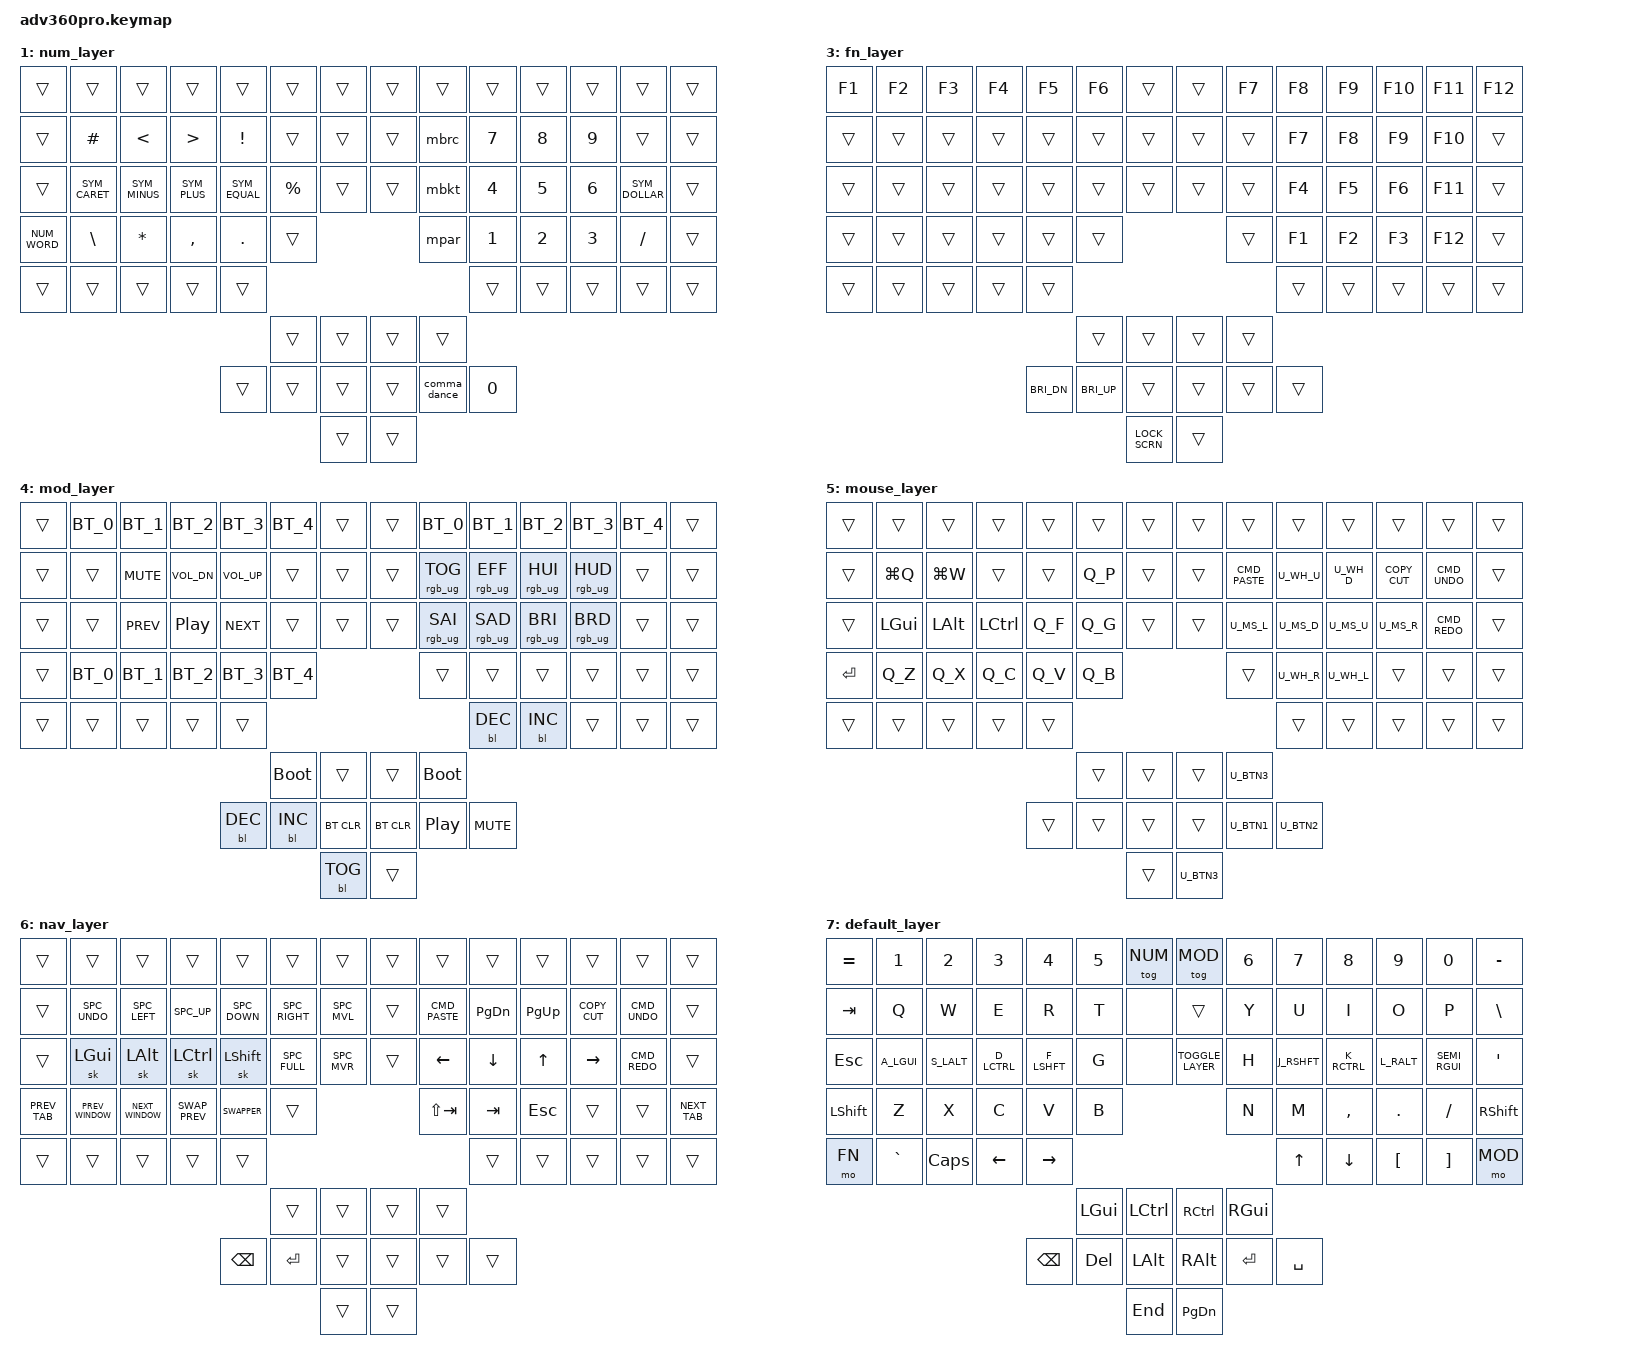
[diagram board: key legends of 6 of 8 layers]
#include <behaviors.dtsi>
#include <dt-bindings/zmk/keys.h>
#include <dt-bindings/zmk/bt.h>
#include <dt-bindings/zmk/outputs.h>
#include <dt-bindings/zmk/rgb.h>
#include <dt-bindings/zmk/backlight.h>

#include "adv360pro_keypos.h"
#include "zmk_helper.h"

/* definitions for mouse layer */
#include "mouse.h"

#define ___ &trans

/* Layer references  */
#define QWERTY 0
#define NUM 1
#define SYM 2
#define FN 3
#define MOD 4
#define MS 5
#define NAV 6
#define DEFAULT 7

/* Global settings */
#include "general.h"

/* Home row mods */
#include "homerow_mods.h"

/* Macros and shortcuts */
#include "custom_behaviors.h"

/ {
    /* use urobs matrix transform for correct key mapping */
    chosen {
        zmk,matrix_transform = &urobs_transform;
    };

    keymap {
        compatible = "zmk,keymap";

// QWERTY base
        base_layer {
            bindings = <
// ╭─────────────╮╭─────────────┬─────────────┬─────────────┬─────────────┬─────────────╮╭─────────────╮  ╭─────────────╮╭─────────────┬─────────────┬─────────────┬─────────────┬─────────────╮╭─────────────╮
     &kp EQUAL        &kp N1        &kp N2        &kp N3        &kp N4        &kp N5         &tog NUM         &mo MOD        &kp N6        &kp N7        &kp N8        &kp N9        &kp N0         LOCK_SCRN
// ╰─────────────╯╰─────────────┴─────────────┴─────────────┴─────────────┴─────────────╯╰─────────────╯  ╰─────────────╯╰─────────────┴─────────────┴─────────────┴─────────────┴─────────────╯╰─────────────╯
// ╭─────────────╮╭─────────────┬─────────────┬─────────────┬─────────────┬─────────────╮╭─────────────╮  ╭─────────────╮╭─────────────┬─────────────┬─────────────┬─────────────┬─────────────╮╭─────────────╮
     &kp TAB          &kp Q         &kp W         &kp E         &kp R         &kp T          SWAP_PREV        &tog MS        &kp Y         &kp U         &kp I         &kp O         &kp P          &kp BSLH
// ├─────────────┤├─────────────┼─────────────┼─────────────┼─────────────┼─────────────┤├─────────────┤  ├─────────────┤├─────────────┼─────────────┼─────────────┼─────────────┼─────────────┤├─────────────┤
     &kp ESC          A_LGUI        S_LALT        D_LCTRL       F_LSHFT       &kp G          SWAPPER          TOGGLE_LAYER   &kp H         J_RSHFT       K_RCTRL       L_RALT        SEMI_RGUI      &kp SQT
// ├─────────────┤├─────────────┼─────────────┼─────────────┼─────────────┼─────────────┤╰─────────────╯  ╰─────────────╯├─────────────┼─────────────┼─────────────┼─────────────┼─────────────┤├─────────────┤
     NUM_WORD         &kp Z         &kp X         &kp C         &kp V         &kp B                                          &kp N         &kp M         &kp COMMA     &kp DOT       &kp FSLH       &caps_dance
// ╰─────────────╯╰─────────────┴─────────────┴─────────────┴─────────────┴─────────────╯                                ╰─────────────┴─────────────┴─────────────┴─────────────┴─────────────╯╰─────────────╯
// ╭─────────────╮╭─────────────┬─────────────┬─────────────┬─────────────╮                                                            ╭─────────────┬─────────────┬─────────────┬─────────────╮╭─────────────╮
     &mo FN           NUM_WORD      &sk LHYP      &kp LEFT      &kp RIGHT                                                                  &kp UP        &kp DOWN      &sk RHYP      &caps_dance    &mo MOD
// ╰─────────────╯╰─────────────┴─────────────┴─────────────┴─────────────╯╭─────────────┬─────────────╮  ╭─────────────┬─────────────╮╰─────────────┴─────────────┴─────────────┴─────────────╯╰─────────────╯
                                                                             &mo NAV       &caps_dance      NUM_WORD      &mo MS
//                                                           ╭─────────────┼─────────────┼─────────────┤  ├─────────────┼─────────────┼─────────────╮
                                                               BSPC_SYM      SHFT_NUM      &lt MS HOME      &kp END       SPC_NAV       RET_HYP
//                                                           │             │             ├─────────────┤  ├─────────────┤             │             │
                                                                                           &lt MS TAB       &lt FN ESC
//                                                           ╰─────────────┴─────────────┴─────────────╯  ╰─────────────┴─────────────┴─────────────╯
            >;
        };


        num_layer {
            bindings = <
// ╭─────────────╮╭─────────────┬─────────────┬─────────────┬─────────────┬─────────────╮╭─────────────╮  ╭─────────────╮╭─────────────┬─────────────┬─────────────┬─────────────┬─────────────╮╭─────────────╮
     ___              ___           ___           ___           ___           ___             ___              ___            ___           ___           ___           ___           ___            ___
// ╰─────────────╯╰─────────────┴─────────────┴─────────────┴─────────────┴─────────────╯╰─────────────╯  ╰─────────────╯╰─────────────┴─────────────┴─────────────┴─────────────┴─────────────╯╰─────────────╯
// ╭─────────────╮╭─────────────┬─────────────┬─────────────┬─────────────┬─────────────╮╭─────────────╮  ╭─────────────╮╭─────────────┬─────────────┬─────────────┬─────────────┬─────────────╮╭─────────────╮
     ___              &kp HASH      &kp LT        &kp GT        &kp EXCL      ___             ___              ___            &mbrc         &kp N7        &kp N8        &kp N9        ___            ___
// ├─────────────┤├─────────────┼─────────────┼─────────────┼─────────────┼─────────────┤├─────────────┤  ├─────────────┤├─────────────┼─────────────┼─────────────┼─────────────┼─────────────┤├─────────────┤
     ___              SYM_CARET     SYM_MINUS     SYM_PLUS      SYM_EQUAL     &kp PERCENT     ___              ___            &mbkt         &kp N4        &kp N5        &kp N6        SYM_DOLLAR     ___
// ├─────────────┤├─────────────┼─────────────┼─────────────┼─────────────┼─────────────┤╰─────────────╯  ╰─────────────╯├─────────────┼─────────────┼─────────────┼─────────────┼─────────────┤├─────────────┤
     NUM_WORD         &kp BSLH      &kp STAR      &kp COMMA     &kp DOT       ___                                             &mpar         &kp N1        &kp N2        &kp N3        &kp FSLH       ___
// ╰─────────────╯╰─────────────┴─────────────┴─────────────┴─────────────┴─────────────╯                                ╰─────────────┴─────────────┴─────────────┴─────────────┴─────────────╯╰─────────────╯
// ╭─────────────╮╭─────────────┬─────────────┬─────────────┬─────────────╮                                                            ╭─────────────┬─────────────┬─────────────┬─────────────╮╭─────────────╮
     ___              ___           ___           ___           ___                                                                        ___           ___           ___           ___            ___
// ╰─────────────╯╰─────────────┴─────────────┴─────────────┴─────────────╯╭─────────────┬─────────────╮  ╭─────────────┬─────────────╮╰─────────────┴─────────────┴─────────────┴─────────────╯╰─────────────╯
                                                                             ___           ___              ___           ___
//                                                           ╭─────────────┼─────────────┼─────────────┤  ├─────────────┼─────────────┼─────────────╮
                                                               ___           ___           ___              ___           &comma_dance  &kp N0
//                                                           │             │             ├─────────────┤  ├─────────────┤             │             │
                                                                                           ___              ___
//                                                           ╰─────────────┴─────────────┴─────────────╯  ╰─────────────┴─────────────┴─────────────╯
            >;
        };

        sym_layer {
          bindings = <
// ╭─────────────╮╭─────────────┬─────────────┬─────────────┬─────────────┬─────────────╮╭─────────────╮  ╭─────────────╮╭─────────────┬─────────────┬─────────────┬─────────────┬─────────────╮╭─────────────╮
     ___              &kp EXCL      &kp AT        &kp HASH      &kp DOLLAR    &kp PRCNT      ___              ___            &kp CARET     &kp AMPS      &kp STAR      ___           ___            ___
// ╰─────────────╯╰─────────────┴─────────────┴─────────────┴─────────────┴─────────────╯╰─────────────╯  ╰─────────────╯╰─────────────┴─────────────┴─────────────┴─────────────┴─────────────╯╰─────────────╯
// ╭─────────────╮╭─────────────┬─────────────┬─────────────┬─────────────┬─────────────╮╭─────────────╮  ╭─────────────╮╭─────────────┬─────────────┬─────────────┬─────────────┬─────────────╮╭─────────────╮
     ___              &kp HASH      &kp LT        &kp GT        &kp EXCL      ___            ___              ___            &mbrc         &kp LBRC      &kp RBRC      &kp GRAVE     &msqt_morph    ___
// ├─────────────┤├─────────────┼─────────────┼─────────────┼─────────────┼─────────────┤├─────────────┤  ├─────────────┤├─────────────┼─────────────┼─────────────┼─────────────┼─────────────┤├─────────────┤
     ___              SYM_CARET     SYM_MINUS     SYM_PLUS      SYM_EQUAL     &kp PRCNT      ___              ___            &mbkt         SYM_LBKT      SYM_RBKT      SYM_AT        SYM_DOLLAR     ___
// ├─────────────┤├─────────────┼─────────────┼─────────────┼─────────────┼─────────────┤╰─────────────╯  ╰─────────────╯├─────────────┼─────────────┼─────────────┼─────────────┼─────────────┤├─────────────┤
     ___              &kp BSLH      &kp STAR      &kp PIPE      &kp AMPS      &kp TILDE                                      &mpar         &kp LPAR      &kp RPAR      ___           &kp FSLH       ___
// ╰─────────────╯╰─────────────┴─────────────┴─────────────┴─────────────┴─────────────╯                                ╰─────────────┴─────────────┴─────────────┴─────────────┴─────────────╯╰─────────────╯
// ╭─────────────╮╭─────────────┬─────────────┬─────────────┬─────────────╮                                                            ╭─────────────┬─────────────┬─────────────┬─────────────╮╭─────────────╮
     ___              ___           ___           ___           ___                                                                        &kp LT        &kp GT        ___           ___            ___
// ╰─────────────╯╰─────────────┴─────────────┴─────────────┴─────────────╯╭─────────────┬─────────────╮  ╭─────────────┬─────────────╮╰─────────────┴─────────────┴─────────────┴─────────────╯╰─────────────╯
                                                                             ___           ___              ___           ___
//                                                           ╭─────────────┼─────────────┼─────────────┤  ├─────────────┼─────────────┼─────────────╮
                                                               ___           ___           ___              ___           &kp UNDER     &key_repeat
//                                                           │             │             ├─────────────┤  ├─────────────┤             │             │
                                                                                           ___              ___
//                                                           ╰─────────────┴─────────────┴─────────────╯  ╰─────────────┴─────────────┴─────────────╯
            >;
        };

        fn_layer {
            bindings = <
// ╭─────────────╮╭─────────────┬─────────────┬─────────────┬─────────────┬─────────────╮╭─────────────╮  ╭─────────────╮╭─────────────┬─────────────┬─────────────┬─────────────┬─────────────╮╭─────────────╮
     &kp F1           &kp F2        &kp F3        &kp F4        &kp F5        &kp F6         ___              ___            &kp F7        &kp F8        &kp F9        &kp F10       &kp F11        &kp F12
// ╰─────────────╯╰─────────────┴─────────────┴─────────────┴─────────────┴─────────────╯╰─────────────╯  ╰─────────────╯╰─────────────┴─────────────┴─────────────┴─────────────┴─────────────╯╰─────────────╯
// ╭─────────────╮╭─────────────┬─────────────┬─────────────┬─────────────┬─────────────╮╭─────────────╮  ╭─────────────╮╭─────────────┬─────────────┬─────────────┬─────────────┬─────────────╮╭─────────────╮
     ___              ___           ___           ___           ___           ___            ___              ___            ___           &kp F7        &kp F8        &kp F9        &kp F10        ___
// ├─────────────┤├─────────────┼─────────────┼─────────────┼─────────────┼─────────────┤├─────────────┤  ├─────────────┤├─────────────┼─────────────┼─────────────┼─────────────┼─────────────┤├─────────────┤
     ___              ___           ___           ___           ___           ___            ___              ___            ___           &kp F4        &kp F5        &kp F6        &kp F11        ___
// ├─────────────┤├─────────────┼─────────────┼─────────────┼─────────────┼─────────────┤╰─────────────╯  ╰─────────────╯├─────────────┼─────────────┼─────────────┼─────────────┼─────────────┤├─────────────┤
     ___              ___           ___           ___           ___           ___                                            ___           &kp F1        &kp F2        &kp F3        &kp F12        ___
// ╰─────────────╯╰─────────────┴─────────────┴─────────────┴─────────────┴─────────────╯                                ╰─────────────┴─────────────┴─────────────┴─────────────┴─────────────╯╰─────────────╯
// ╭─────────────╮╭─────────────┬─────────────┬─────────────┬─────────────╮                                                            ╭─────────────┬─────────────┬─────────────┬─────────────╮╭─────────────╮
     ___              ___           ___           ___           ___                                                                        ___           ___           ___           ___            ___
// ╰─────────────╯╰─────────────┴─────────────┴─────────────┴─────────────╯╭─────────────┬─────────────╮  ╭─────────────┬─────────────╮╰─────────────┴─────────────┴─────────────┴─────────────╯╰─────────────╯
                                                                             ___           ___              ___           ___
//                                                           ╭─────────────┼─────────────┼─────────────┤  ├─────────────┼─────────────┼─────────────╮
                                                               &kp C_BRI_DN  &kp C_BRI_UP  ___              ___           ___           ___
//                                                           │             │             ├─────────────┤  ├─────────────┤             │             │
                                                                                           LOCK_SCRN        ___
//                                                           ╰─────────────┴─────────────┴─────────────╯  ╰─────────────┴─────────────┴─────────────╯
            >;
        };

        mod_layer {
            bindings = <
// ╭─────────────╮╭─────────────┬─────────────┬─────────────┬─────────────┬─────────────╮╭─────────────╮  ╭─────────────╮╭─────────────┬─────────────┬─────────────┬─────────────┬─────────────╮╭─────────────╮
     ___              BT_0          BT_1          BT_2          BT_3          BT_4           ___              ___            BT_0          BT_1          BT_2          BT_3          BT_4           ___
// ╰─────────────╯╰─────────────┴─────────────┴─────────────┴─────────────┴─────────────╯╰─────────────╯  ╰─────────────╯╰─────────────┴─────────────┴─────────────┴─────────────┴─────────────╯╰─────────────╯
// ╭─────────────╮╭─────────────┬─────────────┬─────────────┬─────────────┬─────────────╮╭─────────────╮  ╭─────────────╮╭─────────────┬─────────────┬─────────────┬─────────────┬─────────────╮╭─────────────╮
     ___              ___           &kp C_MUTE    &kp C_VOL_DN  &kp C_VOL_UP  ___            ___              ___            &rgb_ug RGB_TOG &rgb_ug RGB_EFF &rgb_ug RGB_HUI &rgb_ug RGB_HUD ___            ___
// ├─────────────┤├─────────────┼─────────────┼─────────────┼─────────────┼─────────────┤├─────────────┤  ├─────────────┤├─────────────┼─────────────┼─────────────┼─────────────┼─────────────┤├─────────────┤
     ___              ___           &kp C_PREV    &kp C_PP      &kp C_NEXT    ___            ___              ___            &rgb_ug RGB_SAI &rgb_ug RGB_SAD &rgb_ug RGB_BRI &rgb_ug RGB_BRD ___            ___
// ├─────────────┤├─────────────┼─────────────┼─────────────┼─────────────┼─────────────┤╰─────────────╯  ╰─────────────╯├─────────────┼─────────────┼─────────────┼─────────────┼─────────────┤├─────────────┤
     ___              BT_0          BT_1          BT_2          BT_3          BT_4                                           ___           ___           ___           ___           ___            ___
// ╰─────────────╯╰─────────────┴─────────────┴─────────────┴─────────────┴─────────────╯                                ╰─────────────┴─────────────┴─────────────┴─────────────┴─────────────╯╰─────────────╯
// ╭─────────────╮╭─────────────┬─────────────┬─────────────┬─────────────╮                                                            ╭─────────────┬─────────────┬─────────────┬─────────────╮╭─────────────╮
     ___              ___           ___           ___           ___                                                                        &bl BL_DEC    &bl BL_INC    ___           ___            ___
// ╰─────────────╯╰─────────────┴─────────────┴─────────────┴─────────────╯╭─────────────┬─────────────╮  ╭─────────────┬─────────────╮╰─────────────┴─────────────┴─────────────┴─────────────╯╰─────────────╯
                                                                             &bootloader   ___              ___           &bootloader
//                                                           ╭─────────────┼─────────────┼─────────────┤  ├─────────────┼─────────────┼─────────────╮
                                                               &bl BL_DEC    &bl BL_INC    &bt BT_CLR       &bt BT_CLR    &kp C_PP      &kp C_MUTE
//                                                           │             │             ├─────────────┤  ├─────────────┤             │             │
                                                                                           &bl BL_TOG      ___
//                                                           ╰─────────────┴─────────────┴─────────────╯  ╰─────────────┴─────────────┴─────────────╯
            >;
        };

        mouse_layer {
            bindings = <
// ╭─────────────╮╭─────────────┬─────────────┬─────────────┬─────────────┬─────────────╮╭─────────────╮  ╭─────────────╮╭─────────────┬─────────────┬─────────────┬─────────────┬─────────────╮╭─────────────╮
     ___              ___           ___           ___           ___           ___            ___              ___            ___           ___           ___           ___           ___            ___
// ╰─────────────╯╰─────────────┴─────────────┴─────────────┴─────────────┴─────────────╯╰─────────────╯  ╰─────────────╯╰─────────────┴─────────────┴─────────────┴─────────────┴─────────────╯╰─────────────╯
// ╭─────────────╮╭─────────────┬─────────────┬─────────────┬─────────────┬─────────────╮╭─────────────╮  ╭─────────────╮╭─────────────┬─────────────┬─────────────┬─────────────┬─────────────╮╭─────────────╮
     ___              &kp LG(Q)     &kp LG(W)     ___           ___           Q_P            ___              ___            CMD_PASTE     U_WH_U        U_WH_D        COPY_CUT      CMD_UNDO       ___
// ├─────────────┤├─────────────┼─────────────┼─────────────┼─────────────┼─────────────┤├─────────────┤  ├─────────────┤├─────────────┼─────────────┼─────────────┼─────────────┼─────────────┤├─────────────┤
     ___              &kp LGUI      &kp LALT      &kp LCTRL     Q_F           Q_G            ___              ___            U_MS_L        U_MS_D        U_MS_U        U_MS_R        CMD_REDO       ___
// ├─────────────┤├─────────────┼─────────────┼─────────────┼─────────────┼─────────────┤╰─────────────╯  ╰─────────────╯├─────────────┼─────────────┼─────────────┼─────────────┼─────────────┤├─────────────┤
     &kp ENTER        Q_Z           Q_X           Q_C           Q_V           Q_B                                            ___           U_WH_R        U_WH_L        ___           ___            ___
// ╰─────────────╯╰─────────────┴─────────────┴─────────────┴─────────────┴─────────────╯                                ╰─────────────┴─────────────┴─────────────┴─────────────┴─────────────╯╰─────────────╯
// ╭─────────────╮╭─────────────┬─────────────┬─────────────┬─────────────╮                                                            ╭─────────────┬─────────────┬─────────────┬─────────────╮╭─────────────╮
     ___              ___           ___           ___           ___                                                                        ___           ___           ___           ___            ___
// ╰─────────────╯╰─────────────┴─────────────┴─────────────┴─────────────╯╭─────────────┬─────────────╮  ╭─────────────┬─────────────╮╰─────────────┴─────────────┴─────────────┴─────────────╯╰─────────────╯
                                                                             ___           ___              ___            U_BTN3
//                                                           ╭─────────────┼─────────────┼─────────────┤  ├─────────────┼─────────────┼─────────────╮
                                                               ___           ___           ___              ___            U_BTN1        U_BTN2
//                                                           │             │             ├─────────────┤  ├─────────────┤             │             │
                                                                                           ___              U_BTN3
//                                                           ╰─────────────┴─────────────┴─────────────╯  ╰─────────────┴─────────────┴─────────────╯
            >;
        };

        nav_layer {
            bindings = <
// ╭─────────────╮╭─────────────┬─────────────┬─────────────┬─────────────┬─────────────╮╭─────────────╮  ╭─────────────╮╭─────────────┬─────────────┬─────────────┬─────────────┬─────────────╮╭─────────────╮
     ___              ___           ___           ___           ___           ___            ___              ___            ___           ___           ___           ___           ___            ___
// ╰─────────────╯╰─────────────┴─────────────┴─────────────┴─────────────┴─────────────╯╰─────────────╯  ╰─────────────╯╰─────────────┴─────────────┴─────────────┴─────────────┴─────────────╯╰─────────────╯
// ╭─────────────╮╭─────────────┬─────────────┬─────────────┬─────────────┬─────────────╮╭─────────────╮  ╭─────────────╮╭─────────────┬─────────────┬─────────────┬─────────────┬─────────────╮╭─────────────╮
     ___              SPC_UNDO      SPC_LEFT      SPC_UP        SPC_DOWN      SPC_RIGHT      SPC_MVL          ___            CMD_PASTE     &kp PG_DN     &kp PG_UP     COPY_CUT      CMD_UNDO       ___
// ├─────────────┤├─────────────┼─────────────┼─────────────┼─────────────┼─────────────┤├─────────────┤  ├─────────────┤├─────────────┼─────────────┼─────────────┼─────────────┼─────────────┤├─────────────┤
     ___              &sk LGUI      &sk LALT      &sk LCTRL     &sk LSHFT     SPC_FULL       SPC_MVR          ___            &kp LEFT      &kp DOWN      &kp UP        &kp RIGHT     CMD_REDO       ___
// ├─────────────┤├─────────────┼─────────────┼─────────────┼─────────────┼─────────────┤╰─────────────╯  ╰─────────────╯├─────────────┼─────────────┼─────────────┼─────────────┼─────────────┤├─────────────┤
     PREV_TAB         PREV_WINDOW   NEXT_WINDOW   SWAP_PREV     SWAPPER       ___                                            &kp LS(TAB)   &kp TAB       &kp ESC       ___           ___            NEXT_TAB
// ╰─────────────╯╰─────────────┴─────────────┴─────────────┴─────────────┴─────────────╯                                ╰─────────────┴─────────────┴─────────────┴─────────────┴─────────────╯╰─────────────╯
// ╭─────────────╮╭─────────────┬─────────────┬─────────────┬─────────────╮                                                            ╭─────────────┬─────────────┬─────────────┬─────────────╮╭─────────────╮
     ___              ___           ___           ___           ___                                                                        ___           ___           ___           ___            ___
// ╰─────────────╯╰─────────────┴─────────────┴─────────────┴─────────────╯╭─────────────┬─────────────╮  ╭─────────────┬─────────────╮╰─────────────┴─────────────┴─────────────┴─────────────╯╰─────────────╯
                                                                             ___           ___              ___           ___
//                                                           ╭─────────────┼─────────────┼─────────────┤  ├─────────────┼─────────────┼─────────────╮
                                                               &kp BSPC      &kp ENTER     ___              ___           ___           ___
//                                                           │             │             ├─────────────┤  ├─────────────┤             │             │
                                                                                           ___              ___
//                                                           ╰─────────────┴─────────────┴─────────────╯  ╰─────────────┴─────────────┴─────────────╯
            >;
        };

        default_layer {
            bindings = <
// ╭─────────────╮╭─────────────┬─────────────┬─────────────┬─────────────┬─────────────╮╭─────────────╮  ╭─────────────╮╭─────────────┬─────────────┬─────────────┬─────────────┬─────────────╮╭─────────────╮
     &kp EQUAL        &kp N1        &kp N2        &kp N3        &kp N4        &kp N5         &tog NUM         &tog MOD        &kp N6        &kp N7        &kp N8        &kp N9        &kp N0         &kp MINUS
// ╰─────────────╯╰─────────────┴─────────────┴─────────────┴─────────────┴─────────────╯╰─────────────╯  ╰─────────────╯╰─────────────┴─────────────┴─────────────┴─────────────┴─────────────╯╰─────────────╯
// ╭─────────────╮╭─────────────┬─────────────┬─────────────┬─────────────┬─────────────╮╭─────────────╮  ╭─────────────╮╭─────────────┬─────────────┬─────────────┬─────────────┬─────────────╮╭─────────────╮
     &kp TAB          &kp Q         &kp W         &kp E         &kp R         &kp T          &none            ___             &kp Y         &kp U         &kp I         &kp O         &kp P          &kp BSLH
// ├─────────────┤├─────────────┼─────────────┼─────────────┼─────────────┼─────────────┤├─────────────┤  ├─────────────┤├─────────────┼─────────────┼─────────────┼─────────────┼─────────────┤├─────────────┤
     &kp ESC          A_LGUI        S_LALT        D_LCTRL       F_LSHFT       &kp G          &none            TOGGLE_LAYER    &kp H         J_RSHFT       K_RCTRL       L_RALT        SEMI_RGUI      &kp SQT
// ├─────────────┤├─────────────┼─────────────┼─────────────┼─────────────┼─────────────┤╰─────────────╯  ╰─────────────╯├─────────────┼─────────────┼─────────────┼─────────────┼─────────────┤├─────────────┤
     &kp LSHFT        &kp Z         &kp X         &kp C         &kp V         &kp B                                           &kp N         &kp M         &kp COMMA     &kp DOT       &kp FSLH       &kp RSHFT
// ╰─────────────╯╰─────────────┴─────────────┴─────────────┴─────────────┴─────────────╯                                ╰─────────────┴─────────────┴─────────────┴─────────────┴─────────────╯╰─────────────╯
// ╭─────────────╮╭─────────────┬─────────────┬─────────────┬─────────────╮                                                            ╭─────────────┬─────────────┬─────────────┬─────────────╮╭─────────────╮
     &mo FN           &kp GRAVE     &kp CAPS      &kp LEFT      &kp RIGHT                                                                  &kp UP        &kp DOWN      &kp LBKT      &kp RBKT        &mo MOD
// ╰─────────────╯╰─────────────┴─────────────┴─────────────┴─────────────╯╭─────────────┬─────────────╮  ╭─────────────┬─────────────╮╰─────────────┴─────────────┴─────────────┴─────────────╯╰─────────────╯
                                                                             &kp LGUI      &kp LCTRL         &kp RCTRL     &kp RGUI
//                                                           ╭─────────────┼─────────────┼─────────────┤  ├─────────────┼─────────────┼─────────────╮
                                                               &kp BSPC      &kp DEL        &kp LALT         &kp RALT     &kp ENTER      &kp SPACE
//                                                           │             │             ├─────────────┤  ├─────────────┤             │             │
                                                                                            &kp END          &kp PG_DN
//                                                           ╰─────────────┴─────────────┴─────────────╯  ╰─────────────┴─────────────┴─────────────╯
            >;
        };

    };



};
